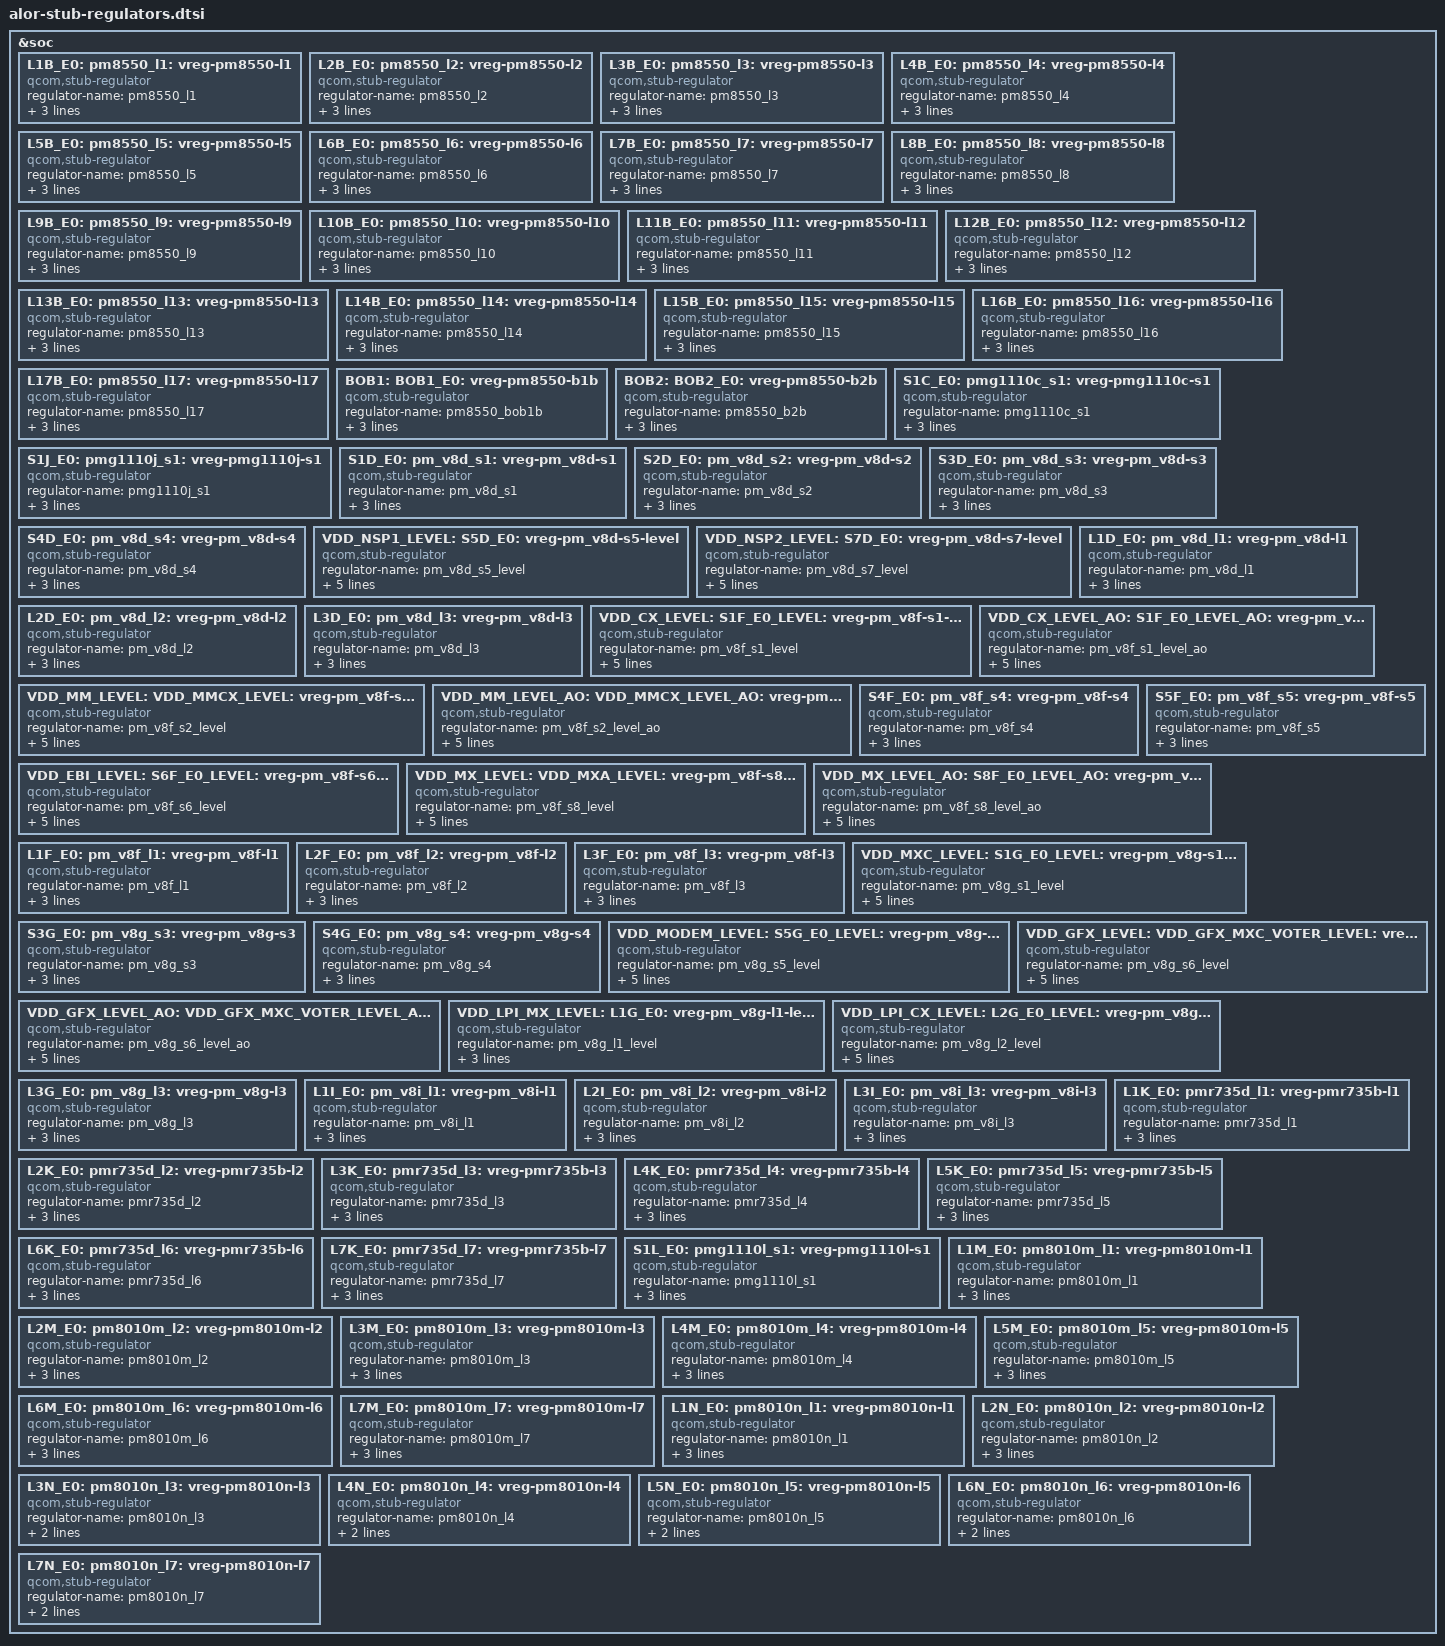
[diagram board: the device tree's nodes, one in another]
// SPDX-License-Identifier: BSD-3-Clause
/*
 * Copyright (c) 2024 Qualcomm Innovation Center, Inc. All rights reserved.
 */

#include <dt-bindings/regulator/qcom,rpmh-regulator-levels.h>

&soc {
		L1B_E0:
		pm8550_l1: vreg-pm8550-l1 {
			compatible = "qcom,stub-regulator";
			regulator-name = "pm8550_l1";
			qcom,hpm-min-load = <10000>;
			regulator-min-microvolt = <1080000>;
			regulator-max-microvolt = <2000000>;
		};

		L2B_E0:
		pm8550_l2: vreg-pm8550-l2 {
			compatible = "qcom,stub-regulator";
			regulator-name = "pm8550_l2";
			qcom,hpm-min-load = <10000>;
			regulator-min-microvolt = <2600000>;
			regulator-max-microvolt = <3544000>;
		};

		L3B_E0:
		pm8550_l3: vreg-pm8550-l3 {
			compatible = "qcom,stub-regulator";
			regulator-name = "pm8550_l3";
			qcom,hpm-min-load = <10000>;
			regulator-min-microvolt = <1170000>;
			regulator-max-microvolt = <1370000>;
		};

		L4B_E0:
		pm8550_l4: vreg-pm8550-l4 {
			compatible = "qcom,stub-regulator";
			regulator-name = "pm8550_l4";
			qcom,hpm-min-load = <10000>;
			regulator-min-microvolt = <1710000>;
			regulator-max-microvolt = <1950000>;
		};

		L5B_E0:
		pm8550_l5: vreg-pm8550-l5 {
			compatible = "qcom,stub-regulator";
			regulator-name = "pm8550_l5";
			qcom,hpm-min-load = <10000>;
			regulator-min-microvolt = <2700000>;
			regulator-max-microvolt = <3544000>;
		};

		L6B_E0:
		pm8550_l6: vreg-pm8550-l6 {
			compatible = "qcom,stub-regulator";
			regulator-name = "pm8550_l6";
			qcom,hpm-min-load = <10000>;
			regulator-min-microvolt = <1504000>;
			regulator-max-microvolt = <3544000>;
		};

		L7B_E0:
		pm8550_l7: vreg-pm8550-l7 {
			compatible = "qcom,stub-regulator";
			regulator-name = "pm8550_l7";
			qcom,hpm-min-load = <10000>;
			regulator-min-microvolt = <1504000>;
			regulator-max-microvolt = <3544000>;
		};

		L8B_E0:
		pm8550_l8: vreg-pm8550-l8 {
			compatible = "qcom,stub-regulator";
			regulator-name = "pm8550_l8";
			qcom,hpm-min-load = <10000>;
			regulator-min-microvolt = <1650000>;
			regulator-max-microvolt = <3544000>;
		};

		L9B_E0:
		pm8550_l9: vreg-pm8550-l9 {
			compatible = "qcom,stub-regulator";
			regulator-name = "pm8550_l9";
			qcom,hpm-min-load = <10000>;
			regulator-min-microvolt = <2700000>;
			regulator-max-microvolt = <3300000>;
		};

		L10B_E0:
		pm8550_l10: vreg-pm8550-l10 {
			compatible = "qcom,stub-regulator";
			regulator-name = "pm8550_l10";
			qcom,hpm-min-load = <10000>;
			regulator-min-microvolt = <1600000>;
			regulator-max-microvolt = <2000000>;
		};

		L11B_E0:
		pm8550_l11: vreg-pm8550-l11 {
			compatible = "qcom,stub-regulator";
			regulator-name = "pm8550_l11";
			qcom,hpm-min-load = <10000>;
			regulator-min-microvolt = <1030000>;
			regulator-max-microvolt = <1100000>;
		};

		L12B_E0:
		pm8550_l12: vreg-pm8550-l12 {
			compatible = "qcom,stub-regulator";
			regulator-name = "pm8550_l12";
			qcom,hpm-min-load = <10000>;
			regulator-min-microvolt = <1650000>;
			regulator-max-microvolt = <1950000>;
		};

		L13B_E0:
		pm8550_l13: vreg-pm8550-l13 {
			compatible = "qcom,stub-regulator";
			regulator-name = "pm8550_l13";
			qcom,hpm-min-load = <10000>;
			regulator-min-microvolt = <2650000>;
			regulator-max-microvolt = <3544000>;
		};

		L14B_E0:
		pm8550_l14: vreg-pm8550-l14 {
			compatible = "qcom,stub-regulator";
			regulator-name = "pm8550_l14";
			qcom,hpm-min-load = <10000>;
			regulator-min-microvolt = <2700000>;
			regulator-max-microvolt = <3544000>;
		};

		L15B_E0:
		pm8550_l15: vreg-pm8550-l15 {
			compatible = "qcom,stub-regulator";
			regulator-name = "pm8550_l15";
			qcom,hpm-min-load = <10000>;
			regulator-min-microvolt = <1080000>;
			regulator-max-microvolt = <2000000>;
		};

		L16B_E0:
		pm8550_l16: vreg-pm8550-l16 {
			compatible = "qcom,stub-regulator";
			regulator-name = "pm8550_l16";
			qcom,hpm-min-load = <10000>;
			regulator-min-microvolt = <2000000>;
			regulator-max-microvolt = <3544000>;
		};

		L17B_E0:
		pm8550_l17: vreg-pm8550-l17 {
			compatible = "qcom,stub-regulator";
			regulator-name = "pm8550_l17";
			qcom,hpm-min-load = <10000>;
			regulator-min-microvolt = <2400000>;
			regulator-max-microvolt = <3300000>;
		};

		BOB1:
		BOB1_E0:
		B1B_E0:
		pm8550_b1b: vreg-pm8550-b1b {
			compatible = "qcom,stub-regulator";
			regulator-name = "pm8550_bob1b";
			qcom,hpm-min-load = <10000>;
			regulator-min-microvolt = <2500000>;
			regulator-max-microvolt = <4500000>;
		};

		BOB2:
		BOB2_E0:
		B2B_E0:
		pm8550_b2b: vreg-pm8550-b2b {
			compatible = "qcom,stub-regulator";
			regulator-name = "pm8550_b2b";
			qcom,hpm-min-load = <10000>;
			regulator-min-microvolt = <2400000>;
			regulator-max-microvolt = <3440000>;
		};

		S1C_E0:
		pmg1110c_s1: vreg-pmg1110c-s1 {
			compatible = "qcom,stub-regulator";
			regulator-name = "pmg1110c_s1";
			qcom,hpm-min-load = <10000>;
			regulator-min-microvolt = <320000>;
			regulator-max-microvolt = <1352000>;
		};

		S1J_E0:
		pmg1110j_s1: vreg-pmg1110j-s1 {
			compatible = "qcom,stub-regulator";
			regulator-name = "pmg1110j_s1";
			qcom,hpm-min-load = <10000>;
			regulator-min-microvolt = <556000>;
			regulator-max-microvolt = <816000>;
		};

		S1D_E0:
		pm_v8d_s1: vreg-pm_v8d-s1 {
			compatible = "qcom,stub-regulator";
			regulator-name = "pm_v8d_s1";
			qcom,hpm-min-load = <10000>;
			regulator-min-microvolt = <642000>;
			regulator-max-microvolt = <2070000>;
		};

		S2D_E0:
		pm_v8d_s2: vreg-pm_v8d-s2 {
			compatible = "qcom,stub-regulator";
			regulator-name = "pm_v8d_s2";
			qcom,hpm-min-load = <10000>;
			regulator-min-microvolt = <690000>;
			regulator-max-microvolt = <2100000>;
		};

		S3D_E0:
		pm_v8d_s3: vreg-pm_v8d-s3 {
			compatible = "qcom,stub-regulator";
			regulator-name = "pm_v8d_s3";
			qcom,hpm-min-load = <10000>;
			regulator-min-microvolt = <700000>;
			regulator-max-microvolt = <2700000>;
		};

		S4D_E0:
		pm_v8d_s4: vreg-pm_v8d-s4 {
			compatible = "qcom,stub-regulator";
			regulator-name = "pm_v8d_s4";
			qcom,hpm-min-load = <10000>;
			regulator-min-microvolt = <1700000>;
			regulator-max-microvolt = <2100000>;
		};

		VDD_NSP1_LEVEL:
		S5D_E0:
		pm_v8d_s5_level: vreg-pm_v8d-s5-level {
			compatible = "qcom,stub-regulator";
			regulator-name = "pm_v8d_s5_level";
			qcom,hpm-min-load = <10000>;
			regulator-min-microvolt = <RPMH_REGULATOR_LEVEL_RETENTION>;
			regulator-max-microvolt = <RPMH_REGULATOR_LEVEL_MAX>;
		};

		VDD_NSP2_LEVEL:
		S7D_E0:
		pm_v8d_s7_level: vreg-pm_v8d-s7-level {
			compatible = "qcom,stub-regulator";
			regulator-name = "pm_v8d_s7_level";
			qcom,hpm-min-load = <10000>;
			regulator-min-microvolt = <RPMH_REGULATOR_LEVEL_RETENTION>;
			regulator-max-microvolt = <RPMH_REGULATOR_LEVEL_MAX>;
		};

		L1D_E0:
		pm_v8d_l1: vreg-pm_v8d-l1 {
			compatible = "qcom,stub-regulator";
			regulator-name = "pm_v8d_l1";
			qcom,hpm-min-load = <10000>;
			regulator-min-microvolt = <756000>;
			regulator-max-microvolt = <816000>;
		};

		L2D_E0:
		pm_v8d_l2: vreg-pm_v8d-l2 {
			compatible = "qcom,stub-regulator";
			regulator-name = "pm_v8d_l2";
			qcom,hpm-min-load = <10000>;
			regulator-min-microvolt = <1620000>;
			regulator-max-microvolt = <1980000>;
		};

		L3D_E0:
		pm_v8d_l3: vreg-pm_v8d-l3 {
			compatible = "qcom,stub-regulator";
			regulator-name = "pm_v8d_l3";
			qcom,hpm-min-load = <10000>;
			regulator-min-microvolt = <1080000>;
			regulator-max-microvolt = <1980000>;
		};

		VDD_CX_LEVEL:
		S1F_E0_LEVEL:
		pm_v8f_s1_level: vreg-pm_v8f-s1-level {
			compatible = "qcom,stub-regulator";
			regulator-name = "pm_v8f_s1_level";
			qcom,hpm-min-load = <10000>;
			regulator-min-microvolt =
				<RPMH_REGULATOR_LEVEL_RETENTION>;
			regulator-max-microvolt = <RPMH_REGULATOR_LEVEL_MAX>;
		};

		VDD_CX_LEVEL_AO:
		S1F_E0_LEVEL_AO:
		pm_v8f_s1_level_ao: vreg-pm_v8f-s1-level-ao {
			compatible = "qcom,stub-regulator";
			regulator-name = "pm_v8f_s1_level_ao";
			qcom,hpm-min-load = <10000>;
			regulator-min-microvolt =
				<RPMH_REGULATOR_LEVEL_RETENTION>;
			regulator-max-microvolt = <RPMH_REGULATOR_LEVEL_MAX>;
		};

		VDD_MM_LEVEL:
		VDD_MMCX_LEVEL:
		S2F_E0_LEVEL:
		pm_v8f_s2_level: vreg-pm_v8f-s2-level {
			compatible = "qcom,stub-regulator";
			regulator-name = "pm_v8f_s2_level";
			qcom,hpm-min-load = <10000>;
			regulator-min-microvolt =
				<RPMH_REGULATOR_LEVEL_RETENTION>;
			regulator-max-microvolt = <RPMH_REGULATOR_LEVEL_MAX>;
		};

		VDD_MM_LEVEL_AO:
		VDD_MMCX_LEVEL_AO:
		S2F_E0_LEVEL_AO:
		pm_v8f_s2_level_ao: vreg-pm_v8f-s2-level_ao {
			compatible = "qcom,stub-regulator";
			regulator-name = "pm_v8f_s2_level_ao";
			qcom,hpm-min-load = <10000>;
			regulator-min-microvolt =
				<RPMH_REGULATOR_LEVEL_RETENTION>;
			regulator-max-microvolt = <RPMH_REGULATOR_LEVEL_MAX>;
		};

		S4F_E0:
		pm_v8f_s4: vreg-pm_v8f-s4 {
			compatible = "qcom,stub-regulator";
			regulator-name = "pm_v8f_s4";
			qcom,hpm-min-load = <10000>;
			regulator-min-microvolt = <975000>;
			regulator-max-microvolt = <2100000>;
		};

		S5F_E0:
		pm_v8f_s5: vreg-pm_v8f-s5 {
			compatible = "qcom,stub-regulator";
			regulator-name = "pm_v8f_s5";
			qcom,hpm-min-load = <10000>;
			regulator-min-microvolt = <1010000>;
			regulator-max-microvolt = <1120000>;
		};

		VDD_EBI_LEVEL:
		S6F_E0_LEVEL:
		pm_v8f_s6_level: vreg-pm_v8f-s6-level {
			compatible = "qcom,stub-regulator";
			regulator-name = "pm_v8f_s6_level";
			qcom,hpm-min-load = <10000>;
			regulator-min-microvolt =
				<RPMH_REGULATOR_LEVEL_RETENTION>;
			regulator-max-microvolt = <RPMH_REGULATOR_LEVEL_MAX>;
		};

		VDD_MX_LEVEL:
		VDD_MXA_LEVEL:
		S8F_E0_LEVEL:
		pm_v8f_s8_level: vreg-pm_v8f-s8-level {
			compatible = "qcom,stub-regulator";
			regulator-name = "pm_v8f_s8_level";
			qcom,hpm-min-load = <10000>;
			regulator-min-microvolt =
				<RPMH_REGULATOR_LEVEL_RETENTION>;
			regulator-max-microvolt = <RPMH_REGULATOR_LEVEL_MAX>;
		};

		VDD_MX_LEVEL_AO:
		S8F_E0_LEVEL_AO:
		pm_v8f_s8_level_ao: vreg-pm_v8f-s8-level-ao {
			compatible = "qcom,stub-regulator";
			regulator-name = "pm_v8f_s8_level_ao";
			qcom,hpm-min-load = <10000>;
			regulator-min-microvolt =
				<RPMH_REGULATOR_LEVEL_RETENTION>;
			regulator-max-microvolt = <RPMH_REGULATOR_LEVEL_MAX>;
		};

		L1F_E0:
		pm_v8f_l1: vreg-pm_v8f-l1 {
			compatible = "qcom,stub-regulator";
			regulator-name = "pm_v8f_l1";
			qcom,hpm-min-load = <10000>;
			regulator-min-microvolt = <1000000>;
			regulator-max-microvolt = <1980000>;
		};

		L2F_E0:
		pm_v8f_l2: vreg-pm_v8f-l2 {
			compatible = "qcom,stub-regulator";
			regulator-name = "pm_v8f_l2";
			qcom,hpm-min-load = <10000>;
			regulator-min-microvolt = <1080000>;
			regulator-max-microvolt = <1836000>;
		};

		L3F_E0:
		pm_v8f_l3: vreg-pm_v8f-l3 {
			compatible = "qcom,stub-regulator";
			regulator-name = "pm_v8f_l3";
			qcom,hpm-min-load = <10000>;
			regulator-min-microvolt = <1140000>;
			regulator-max-microvolt = <2000000>;
		};

		VDD_MXC_LEVEL:
		S1G_E0_LEVEL:
		VDD_MXC_MMCX_VOTER_LEVEL:
		VDD_MXC_MM_VOTER_LEVEL:
		VDD_MM_MXC_VOTER_LEVEL:
		VDD_MXC_LEVEL_AO:
		pm_v8g_s1_level: vreg-pm_v8g-s1-level {
			compatible = "qcom,stub-regulator";
			regulator-name = "pm_v8g_s1_level";
			qcom,hpm-min-load = <10000>;
			regulator-min-microvolt =
				<RPMH_REGULATOR_LEVEL_RETENTION>;
			regulator-max-microvolt = <RPMH_REGULATOR_LEVEL_MAX>;
		};

		S3G_E0:
		pm_v8g_s3: vreg-pm_v8g-s3 {
			compatible = "qcom,stub-regulator";
			regulator-name = "pm_v8g_s3";
			qcom,hpm-min-load = <10000>;
			regulator-min-microvolt = <300000>;
			regulator-max-microvolt = <570000>;
		};

		S4G_E0:
		pm_v8g_s4: vreg-pm_v8g-s4 {
			compatible = "qcom,stub-regulator";
			regulator-name = "pm_v8g_s4";
			qcom,hpm-min-load = <10000>;
			regulator-min-microvolt = <870000>;
			regulator-max-microvolt = <970000>;
		};

		VDD_MODEM_LEVEL:
		S5G_E0_LEVEL:
		pm_v8g_s5_level: vreg-pm_v8g-s5-level {
			compatible = "qcom,stub-regulator";
			regulator-name = "pm_v8g_s5_level";
			qcom,hpm-min-load = <10000>;
			regulator-min-microvolt =
					<RPMH_REGULATOR_LEVEL_RETENTION>;
			regulator-max-microvolt =
					<RPMH_REGULATOR_LEVEL_MAX>;
		};

		VDD_GFX_LEVEL:
		VDD_GFX_MXC_VOTER_LEVEL:
		S6G_E0_LEVEL:
		pm_v8g_s6_level: vreg-pm_v8g-s6-level {
			compatible = "qcom,stub-regulator";
			regulator-name = "pm_v8g_s6_level";
			qcom,hpm-min-load = <10000>;
			regulator-min-microvolt =
					<RPMH_REGULATOR_LEVEL_RETENTION>;
			regulator-max-microvolt =
					<RPMH_REGULATOR_LEVEL_MAX>;
		};

		VDD_GFX_LEVEL_AO:
		VDD_GFX_MXC_VOTER_LEVEL_AO:
		S6G_E0_LEVEL_AO:
		pm_v8g_s6_level_ao: vreg-pm_v8g-s6-level_ao {
			compatible = "qcom,stub-regulator";
			regulator-name = "pm_v8g_s6_level_ao";
			qcom,hpm-min-load = <10000>;
			regulator-min-microvolt =
					<RPMH_REGULATOR_LEVEL_RETENTION>;
			regulator-max-microvolt =
					<RPMH_REGULATOR_LEVEL_MAX>;
		};

		VDD_LPI_MX_LEVEL:
		L1G_E0:
		pm_v8g_l1_level: vreg-pm_v8g-l1-level {
			compatible = "qcom,stub-regulator";
			regulator-name = "pm_v8g_l1_level";
			qcom,hpm-min-load = <10000>;
			regulator-min-microvolt = <752000>;
			regulator-max-microvolt = <1980000>;
		};

		VDD_LPI_CX_LEVEL:
		L2G_E0_LEVEL:
		pm_v8g_l2_level: vreg-pm_v8g-l2-level {
			compatible = "qcom,stub-regulator";
			regulator-name = "pm_v8g_l2_level";
			qcom,hpm-min-load = <10000>;
			regulator-min-microvolt =
				<RPMH_REGULATOR_LEVEL_RETENTION>;
			regulator-max-microvolt = <RPMH_REGULATOR_LEVEL_MAX>;
		};

		L3G_E0:
		pm_v8g_l3: vreg-pm_v8g-l3 {
			compatible = "qcom,stub-regulator";
			regulator-name = "pm_v8g_l3";
			qcom,hpm-min-load = <10000>;
			regulator-min-microvolt = <866000>;
			regulator-max-microvolt = <958000>;
		};

		L1I_E0:
		pm_v8i_l1: vreg-pm_v8i-l1 {
			compatible = "qcom,stub-regulator";
			regulator-name = "pm_v8i_l1";
			qcom,hpm-min-load = <10000>;
			regulator-min-microvolt = <866000>;
			regulator-max-microvolt = <958000>;
		};

		L2I_E0:
		pm_v8i_l2: vreg-pm_v8i-l2 {
			compatible = "qcom,stub-regulator";
			regulator-name = "pm_v8i_l2";
			qcom,hpm-min-load = <10000>;
			regulator-min-microvolt = <825000>;
			regulator-max-microvolt = <950000>;
		};

		L3I_E0:
		pm_v8i_l3: vreg-pm_v8i-l3 {
			compatible = "qcom,stub-regulator";
			regulator-name = "pm_v8i_l3";
			qcom,hpm-min-load = <10000>;
			regulator-min-microvolt = <720000>;
			regulator-max-microvolt = <950000>;
		};

		L1K_E0:
		pmr735d_l1: vreg-pmr735b-l1 {
			compatible = "qcom,stub-regulator";
			regulator-name = "pmr735d_l1";
			qcom,hpm-min-load = <10000>;
			regulator-min-microvolt = <806000>;
			regulator-max-microvolt = <901000>;
		};

		L2K_E0:
		pmr735d_l2: vreg-pmr735b-l2 {
			compatible = "qcom,stub-regulator";
			regulator-name = "pmr735d_l2";
			qcom,hpm-min-load = <10000>;
			regulator-min-microvolt = <866000>;
			regulator-max-microvolt = <931000>;
		};

		L3K_E0:
		pmr735d_l3: vreg-pmr735b-l3 {
			compatible = "qcom,stub-regulator";
			regulator-name = "pmr735d_l3";
			qcom,hpm-min-load = <10000>;
			regulator-min-microvolt = <1050000>;
			regulator-max-microvolt = <2000000>;
		};

		L4K_E0:
		pmr735d_l4: vreg-pmr735b-l4 {
			compatible = "qcom,stub-regulator";
			regulator-name = "pmr735d_l4";
			qcom,hpm-min-load = <10000>;
			regulator-min-microvolt = <1080000>;
			regulator-max-microvolt = <1350000>;
		};

		L5K_E0:
		pmr735d_l5: vreg-pmr735b-l5 {
			compatible = "qcom,stub-regulator";
			regulator-name = "pmr735d_l5";
			qcom,hpm-min-load = <10000>;
			regulator-min-microvolt = <920000>;
			regulator-max-microvolt = <969000>;
		};

		L6K_E0:
		pmr735d_l6: vreg-pmr735b-l6 {
			compatible = "qcom,stub-regulator";
			regulator-name = "pmr735d_l6";
			qcom,hpm-min-load = <10000>;
			regulator-min-microvolt = <1050000>;
			regulator-max-microvolt = <2000000>;
		};

		L7K_E0:
		pmr735d_l7: vreg-pmr735b-l7 {
			compatible = "qcom,stub-regulator";
			regulator-name = "pmr735d_l7";
			qcom,hpm-min-load = <10000>;
			regulator-min-microvolt = <556000>;
			regulator-max-microvolt = <816000>;
		};

		S1L_E0:
		pmg1110l_s1: vreg-pmg1110l-s1 {
			compatible = "qcom,stub-regulator";
			regulator-name = "pmg1110l_s1";
			qcom,hpm-min-load = <10000>;
			regulator-min-microvolt = <700000>;
			regulator-max-microvolt = <1352000>;
		};

		L1M_E0:
		pm8010m_l1: vreg-pm8010m-l1 {
			compatible = "qcom,stub-regulator";
			regulator-name = "pm8010m_l1";
			qcom,hpm-min-load = <10000>;
			regulator-min-microvolt = <900000>;
			regulator-max-microvolt = <1100000>;
		};

		L2M_E0:
		pm8010m_l2: vreg-pm8010m-l2 {
			compatible = "qcom,stub-regulator";
			regulator-name = "pm8010m_l2";
			qcom,hpm-min-load = <10000>;
			regulator-min-microvolt = <1000000>;
			regulator-max-microvolt = <1200000>;
		};

		L3M_E0:
		pm8010m_l3: vreg-pm8010m-l3 {
			compatible = "qcom,stub-regulator";
			regulator-name = "pm8010m_l3";
			qcom,hpm-min-load = <10000>;
			regulator-min-microvolt = <2700000>;
			regulator-max-microvolt = <2900000>;
		};

		L4M_E0:
		pm8010m_l4: vreg-pm8010m-l4 {
			compatible = "qcom,stub-regulator";
			regulator-name = "pm8010m_l4";
			qcom,hpm-min-load = <10000>;
			regulator-min-microvolt = <2100000>;
			regulator-max-microvolt = <2300000>;
		};

		L5M_E0:
		pm8010m_l5: vreg-pm8010m-l5 {
			compatible = "qcom,stub-regulator";
			regulator-name = "pm8010m_l5";
			qcom,hpm-min-load = <10000>;
			regulator-min-microvolt = <1300000>;
			regulator-max-microvolt = <1500000>;
		};

		L6M_E0:
		pm8010m_l6: vreg-pm8010m-l6 {
			compatible = "qcom,stub-regulator";
			regulator-name = "pm8010m_l6";
			qcom,hpm-min-load = <10000>;
			regulator-min-microvolt = <2700000>;
			regulator-max-microvolt = <2900000>;
		};

		L7M_E0:
		pm8010m_l7: vreg-pm8010m-l7 {
			compatible = "qcom,stub-regulator";
			regulator-name = "pm8010m_l7";
			qcom,hpm-min-load = <10000>;
			regulator-min-microvolt = <2700000>;
			regulator-max-microvolt = <3000000>;
		};

		L1N_E0:
		pm8010n_l1: vreg-pm8010n-l1 {
			compatible = "qcom,stub-regulator";
			regulator-name = "pm8010n_l1";
			qcom,hpm-min-load = <10000>;
			regulator-min-microvolt = <1050000>;
			regulator-max-microvolt = <1150000>;
		};

		L2N_E0:
		pm8010n_l2: vreg-pm8010n-l2 {
			compatible = "qcom,stub-regulator";
			regulator-name = "pm8010n_l2";
			qcom,hpm-min-load = <10000>;
			regulator-min-microvolt = <1080000>;
			regulator-max-microvolt = <1544000>;
		};

		L3N_E0:
		pm8010n_l3: vreg-pm8010n-l3 {
			compatible = "qcom,stub-regulator";
			regulator-name = "pm8010n_l3";
			regulator-min-microvolt = <1792000>;
			regulator-max-microvolt = <1900000>;
		};

		L4N_E0:
		pm8010n_l4: vreg-pm8010n-l4 {
			compatible = "qcom,stub-regulator";
			regulator-name = "pm8010n_l4";
			regulator-min-microvolt = <1792000>;
			regulator-max-microvolt = <1980000>;
		};

		L5N_E0:
		pm8010n_l5: vreg-pm8010n-l5 {
			compatible = "qcom,stub-regulator";
			regulator-name = "pm8010n_l5";
			regulator-min-microvolt = <2600000>;
			regulator-max-microvolt = <2900000>;
		};

		L6N_E0:
		pm8010n_l6: vreg-pm8010n-l6 {
			compatible = "qcom,stub-regulator";
			regulator-name = "pm8010n_l6";
			regulator-min-microvolt = <2700000>;
			regulator-max-microvolt = <2900000>;
		};

		L7N_E0:
		pm8010n_l7: vreg-pm8010n-l7 {
			compatible = "qcom,stub-regulator";
			regulator-name = "pm8010n_l7";
			regulator-min-microvolt = <3130000>;
			regulator-max-microvolt = <3470000>;
		};
};
